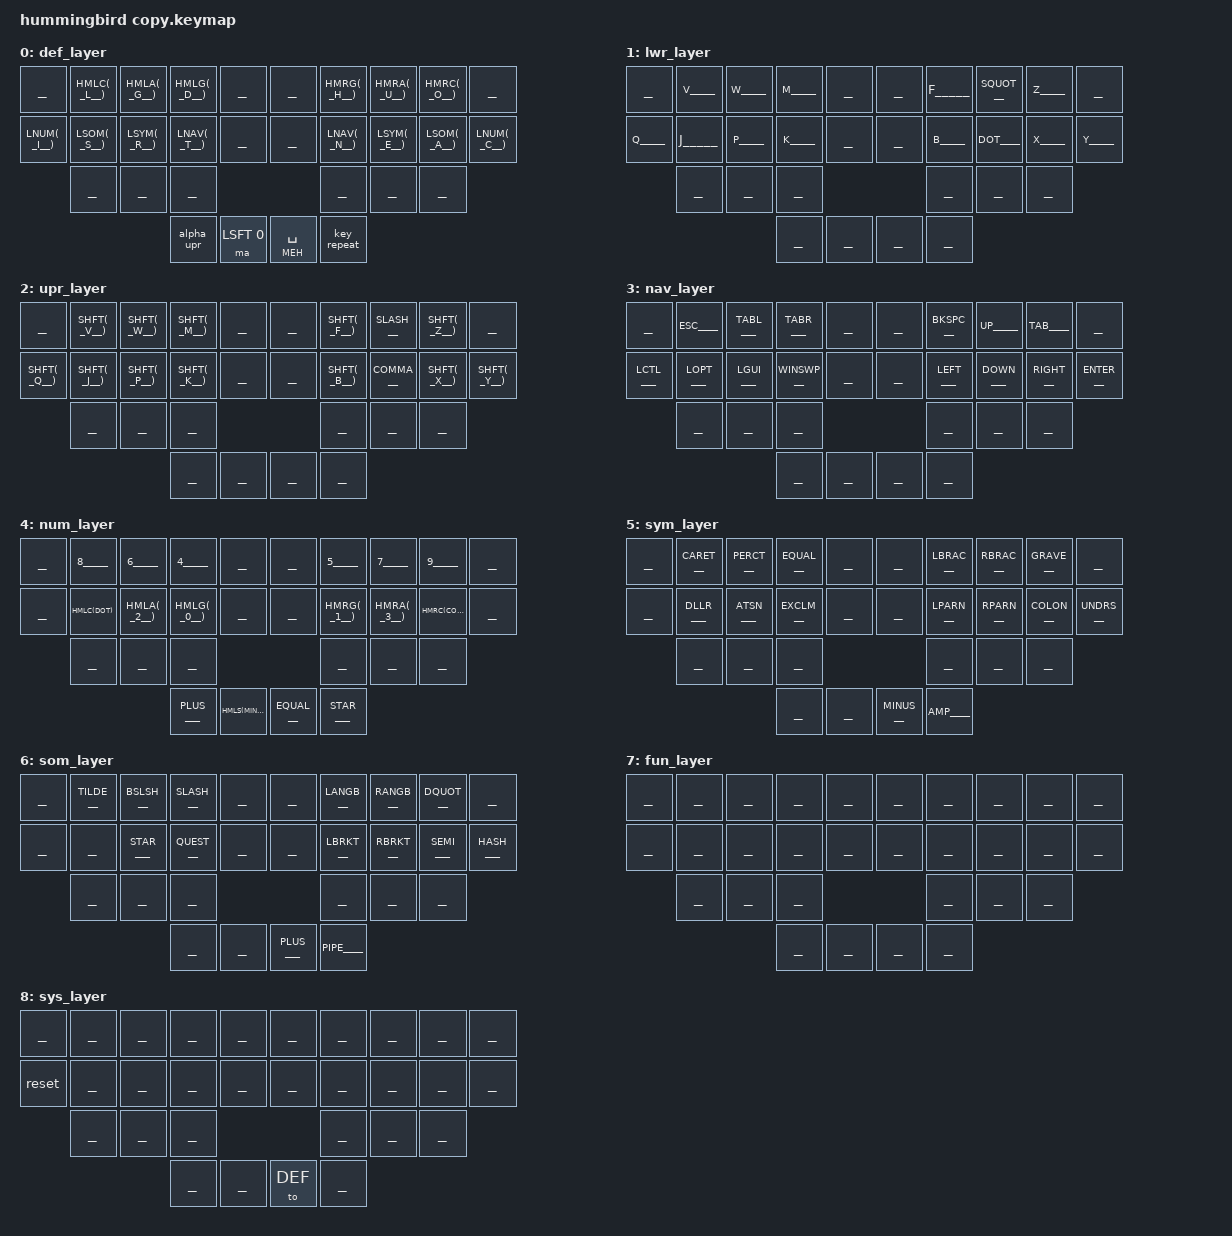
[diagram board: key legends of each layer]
#include <behaviors.dtsi>
#include <dt-bindings/zmk/keys.h>
#include <dt-bindings/zmk/bt.h>

#include "./helpers.h"
#include "./keycodes.h"

#define DEF 0
#define LWR 1
#define UPR 2
#define NAV 3
#define NUM 4
#define SYM 5
#define SOM 6
#define FUN 7
#define SYS 8

&mt {
  tapping-term-ms = <201>;
  flavor = "tap-preferred";
};

&sk {
  release-after-ms = <2000>;
  quick-release;
};

/**
 * Homerow Mod
 */
ZMK_BEHAVIOR(homerow_mod, hold_tap,
  flavor = "tap-preferred";
  tapping-term-ms = <300>;
  quick-tap-ms = <250>;
  bindings = <&kp>, <&kp>;
)

#define HM(LAYER, KEY) &homerow_mod LAYER KEY 

#define HMLG(KEY) &homerow_mod LEFT_GUI      KEY 
#define HMLA(KEY) &homerow_mod LEFT_ALT      KEY 
#define HMLC(KEY) &homerow_mod LEFT_CONTROL  KEY 
#define HMLS(KEY) &homerow_mod LEFT_SHIFT    KEY 

#define HMRG(KEY) &homerow_mod RIGHT_GUI     KEY 
#define HMRA(KEY) &homerow_mod RIGHT_ALT     KEY 
#define HMRC(KEY) &homerow_mod RIGHT_CONTROL KEY 
#define HMRS(KEY) &homerow_mod RIGHT_SHIFT   KEY 

/**
 * Homerow Layer
 */
ZMK_BEHAVIOR(homerow_layer, hold_tap,
  flavor = "tap-preferred";
  tapping-term-ms = <220>;
  quick-tap-ms = <250>;
  bindings = <&mo>, <&kp>;
)

#define HL(LAYER, KEY) &homerow_mod LAYER KEY 

#define LNAV(KEY) &homerow_layer NAV KEY 
#define LNUM(KEY) &homerow_layer NUM KEY 
#define LSYM(KEY) &homerow_layer SYM KEY 
#define LSOM(KEY) &homerow_layer SOM KEY 

/**
 * 
 */
ZMK_BEHAVIOR(alpha_lwr, macro,
  bindings = <&sl LWR>;
)

ZMK_BEHAVIOR(ma, hold_tap,
  flavor = "tap-preferred";
  tapping-term-ms = <220>;
  quick-tap-ms = <250>;
  bindings = <&sk>, <&alpha_lwr>;
)

ZMK_BEHAVIOR(alpha_upr, macro,
  bindings = <&sl UPR>;
)

#define SHFT(KEY) &kp LS(KEY)


ZMK_LAYER(def_layer,
// ╭─────────────┬─────────────┬─────────────┬─────────────┬─────────────╮   ╭─────────────┬─────────────┬─────────────┬─────────────┬─────────────╮
     ___________   HMLC(__L__)   HMLA(__G__)   HMLG(__D__)   ___________       ___________   HMRG(__H__)   HMRA(__U__)   HMRC(__O__)   ___________ 
// ├─────────────┼─────────────┼─────────────┼─────────────┼─────────────┤   ├─────────────┼─────────────┼─────────────┼─────────────┼─────────────┤
     LNUM(__I__)   LSOM(__S__)   LSYM(__R__)   LNAV(__T__)   ___________       ___________   LNAV(__N__)   LSYM(__E__)   LSOM(__A__)   LNUM(__C__) 
// ├─────────────┼─────────────┼─────────────┼─────────────┼─────────────┤   ╰─────────────┼─────────────┼─────────────┼─────────────┼─────────────╯
                   ___________   ___________   ___________                                   ___________   ___________   ___________ 
//               ╰─────────────┼─────────────┼─────────────╯                               ╰─────────────┴─────────────┴─────────────╯
                                               &alpha_upr    &ma LSFT 0        &mt MEH SPC   &key_repeat
//                                           ╰─────────────┴─────────────╯   ╰─────────────┴─────────────╯
)


ZMK_LAYER(lwr_layer,
// ╭─────────────┬─────────────┬─────────────┬─────────────┬─────────────╮   ╭─────────────┬─────────────┬─────────────┬─────────────┬─────────────╮
     ___________   _____V_____   _____W_____   _____M_____   ___________       ___________   _____F_____   ___SQUOT___   _____Z_____   ___________ 
// ├─────────────┼─────────────┼─────────────┼─────────────┼─────────────┤   ├─────────────┼─────────────┼─────────────┼─────────────┼─────────────┤
     _____Q_____   _____J_____   _____P_____   _____K_____   ___________       ___________   _____B_____   ____DOT____   _____X_____   _____Y_____ 
// ├─────────────┼─────────────┼─────────────┼─────────────┼─────────────┤   ╰─────────────┼─────────────┼─────────────┼─────────────┼─────────────╯
                   ___________   ___________   ___________                                   ___________   ___________   ___________ 
//               ╰─────────────┼─────────────┼─────────────╯                               ╰─────────────┴─────────────┴─────────────╯
                                               ___________   ___________       ___________   ___________
//                                           ╰─────────────┴─────────────╯   ╰─────────────┴─────────────╯
)

ZMK_LAYER(upr_layer,
// ╭─────────────┬─────────────┬─────────────┬─────────────┬─────────────╮   ╭─────────────┬─────────────┬─────────────┬─────────────┬─────────────╮
     ___________   SHFT(__V__)   SHFT(__W__)   SHFT(__M__)   ___________       ___________   SHFT(__F__)   ___SLASH___   SHFT(__Z__)   ___________ 
// ├─────────────┼─────────────┼─────────────┼─────────────┼─────────────┤   ├─────────────┼─────────────┼─────────────┼─────────────┼─────────────┤
     SHFT(__Q__)   SHFT(__J__)   SHFT(__P__)   SHFT(__K__)   ___________       ___________   SHFT(__B__)   ___COMMA___   SHFT(__X__)   SHFT(__Y__) 
// ├─────────────┼─────────────┼─────────────┼─────────────┼─────────────┤   ╰─────────────┼─────────────┼─────────────┼─────────────┼─────────────╯
                   ___________   ___________   ___________                                   ___________   ___________   ___________ 
//               ╰─────────────┼─────────────┼─────────────╯                               ╰─────────────┴─────────────┴─────────────╯
                                               ___________   ___________       ___________   ___________
//                                           ╰─────────────┴─────────────╯   ╰─────────────┴─────────────╯
)

ZMK_LAYER(nav_layer,
// ╭─────────────┬─────────────┬─────────────┬─────────────┬─────────────╮   ╭─────────────┬─────────────┬─────────────┬─────────────┬─────────────╮
     ___________   ____ESC____   ___TABL____   ___TABR____   ___________       ___________   ___BKSPC___   ____UP_____   ____TAB____   ___________ 
// ├─────────────┼─────────────┼─────────────┼─────────────┼─────────────┤   ├─────────────┼─────────────┼─────────────┼─────────────┼─────────────┤
     ___LCTL____   ___LOPT____   ___LGUI____   __WINSWP___  ___________       ___________   ___LEFT____   ___DOWN____   ___RIGHT___   ___ENTER___ 
// ├─────────────┼─────────────┼─────────────┼─────────────┼─────────────┤   ╰─────────────┼─────────────┼─────────────┼─────────────┼─────────────╯
                   ___________   ___________   ___________                                   ___________   ___________   ___________ 
//               ╰─────────────┼─────────────┼─────────────╯                               ╰─────────────┴─────────────┴─────────────╯
                                               ___________   ___________       ___________   ___________
//                                           ╰─────────────┴─────────────╯   ╰─────────────┴─────────────╯
)

ZMK_LAYER(num_layer,
// ╭─────────────┬─────────────┬─────────────┬─────────────┬─────────────╮   ╭─────────────┬─────────────┬─────────────┬─────────────┬─────────────╮
     ___________   _____8_____   _____6_____   _____4_____   ___________       ___________   _____5_____   _____7_____   _____9_____   ___________ 
// ├─────────────┼─────────────┼─────────────┼─────────────┼─────────────┤   ├─────────────┼─────────────┼─────────────┼─────────────┼─────────────┤
     ___________   HMLC(DOT)     HMLA(__2__)   HMLG(__0__)   ___________       ___________   HMRG(__1__)   HMRA(__3__)   HMRC(COMMA)   ___________ 
// ├─────────────┼─────────────┼─────────────┼─────────────┼─────────────┤   ╰─────────────┼─────────────┼─────────────┼─────────────┼─────────────╯
                   ___________   ___________   ___________                                   ___________   ___________   ___________ 
//               ╰─────────────┼─────────────┼─────────────╯                               ╰─────────────┴─────────────┴─────────────╯
                                               ___PLUS____   HMLS(MINUS)       ___EQUAL___   ___STAR____
//                                           ╰─────────────┴─────────────╯   ╰─────────────┴─────────────╯
)

ZMK_LAYER(sym_layer,
// ╭─────────────┬─────────────┬─────────────┬─────────────┬─────────────╮   ╭─────────────┬─────────────┬─────────────┬─────────────┬─────────────╮
     ___________   ___CARET___   ___PERCT___   ___EQUAL___   ___________       ___________   ___LBRAC___   ___RBRAC___   ___GRAVE___   ___________ 
// ├─────────────┼─────────────┼─────────────┼─────────────┼─────────────┤   ├─────────────┼─────────────┼─────────────┼─────────────┼─────────────┤
     ___________   ___DLLR____   ___ATSN____   ___EXCLM___   ___________       ___________   ___LPARN___   ___RPARN___   ___COLON___   ___UNDRS___ 
// ├─────────────┼─────────────┼─────────────┼─────────────┼─────────────┤   ╰─────────────┼─────────────┼─────────────┼─────────────┼─────────────╯
                   ___________   ___________   ___________                                   ___________   ___________   ___________ 
//               ╰─────────────┼─────────────┼─────────────╯                               ╰─────────────┴─────────────┴─────────────╯
                                               ___________   ___________       ___MINUS___   ____AMP____
//                                           ╰─────────────┴─────────────╯   ╰─────────────┴─────────────╯
)

ZMK_LAYER(som_layer,
// ╭─────────────┬─────────────┬─────────────┬─────────────┬─────────────╮   ╭─────────────┬─────────────┬─────────────┬─────────────┬─────────────╮
     ___________   ___TILDE___   ___BSLSH___   ___SLASH___   ___________       ___________   ___LANGB___   ___RANGB___   ___DQUOT___   ___________ 
// ├─────────────┼─────────────┼─────────────┼─────────────┼─────────────┤   ├─────────────┼─────────────┼─────────────┼─────────────┼─────────────┤
     ___________   ___________   ___STAR____   ___QUEST___   ___________       ___________   ___LBRKT___   ___RBRKT___   ___SEMI____   ___HASH____ 
// ├─────────────┼─────────────┼─────────────┼─────────────┼─────────────┤   ╰─────────────┼─────────────┼─────────────┼─────────────┼─────────────╯
                   ___________   ___________   ___________                                   ___________   ___________   ___________ 
//               ╰─────────────┼─────────────┼─────────────╯                               ╰─────────────┴─────────────┴─────────────╯
                                               ___________   ___________       ___PLUS____   ___PIPE____
//                                           ╰─────────────┴─────────────╯   ╰─────────────┴─────────────╯
)

ZMK_LAYER(fun_layer,
// ╭─────────────┬─────────────┬─────────────┬─────────────┬─────────────╮   ╭─────────────┬─────────────┬─────────────┬─────────────┬─────────────╮
     ___________   ___________   ___________   ___________   ___________       ___________   ___________   ___________   ___________   ___________ 
// ├─────────────┼─────────────┼─────────────┼─────────────┼─────────────┤   ├─────────────┼─────────────┼─────────────┼─────────────┼─────────────┤
     ___________   ___________   ___________   ___________   ___________       ___________   ___________   ___________   ___________   ___________ 
// ├─────────────┼─────────────┼─────────────┼─────────────┼─────────────┤   ╰─────────────┼─────────────┼─────────────┼─────────────┼─────────────╯
                   ___________   ___________   ___________                                   ___________   ___________   ___________ 
//               ╰─────────────┼─────────────┼─────────────╯                               ╰─────────────┴─────────────┴─────────────╯
                                               ___________   ___________       ___________   ___________
//                                           ╰─────────────┴─────────────╯   ╰─────────────┴─────────────╯
)

ZMK_LAYER(sys_layer,
// ╭─────────────┬─────────────┬─────────────┬─────────────┬─────────────╮   ╭─────────────┬─────────────┬─────────────┬─────────────┬─────────────╮
     ___________   ___________   ___________   ___________   ___________       ___________   ___________   ___________   ___________   ___________ 
// ├─────────────┼─────────────┼─────────────┼─────────────┼─────────────┤   ├─────────────┼─────────────┼─────────────┼─────────────┼─────────────┤
     &reset        ___________   ___________   ___________   ___________       ___________   ___________   ___________   ___________   ___________ 
// ├─────────────┼─────────────┼─────────────┼─────────────┼─────────────┤   ╰─────────────┼─────────────┼─────────────┼─────────────┼─────────────╯
                   ___________   ___________   ___________                                   ___________   ___________   ___________ 
//               ╰─────────────┼─────────────┼─────────────╯                               ╰─────────────┴─────────────┴─────────────╯
                                               ___________   ___________       &to DEF       ___________
//                                           ╰─────────────┴─────────────╯   ╰─────────────┴─────────────╯
)

/*                KEY POSITIONS

  ╭────────────────────╮ ╭────────────────────╮
  │  0   1   2   3   4 │ │  5   6   7   8   9 │
  │ 10  11  12  13  14 │ │ 15  16  17  18  19 │ 
  │     20  21  22     │ │     23  24 25      │
  ╰───────────╮ 26  27 │ │ 28  29 ╭───────────╯
              ╰────────╯ ╰────────╯
*/

ZMK_COMBO(to_sys, &to SYS, 11 12, SYM)



/**
 * TEMPLATES
 
// ╭─────────────┬─────────────┬─────────────┬─────────────┬─────────────╮   ╭─────────────┬─────────────┬─────────────┬─────────────┬─────────────╮
     ___________   ___________   ___________   ___________   ___________       ___________   ___________   ___________   ___________   ___________ 
// ├─────────────┼─────────────┼─────────────┼─────────────┼─────────────┤   ├─────────────┼─────────────┼─────────────┼─────────────┼─────────────┤
     ___________   ___________   ___________   ___________   ___________       ___________   ___________   ___________   ___________   ___________ 
// ├─────────────┼─────────────┼─────────────┼─────────────┼─────────────┤   ╰─────────────┼─────────────┼─────────────┼─────────────┼─────────────╯
                   ___________   ___________   ___________                                   ___________   ___________   ___________ 
//               ╰─────────────┼─────────────┼─────────────╯                               ╰─────────────┴─────────────┴─────────────╯
                                               ___________   ___________       ___________   ___________
//                                           ╰─────────────┴─────────────╯   ╰─────────────┴─────────────╯

// ╭─────────────┬─────────────┬─────────────┬─────────────┬─────────────╮   ╭─────────────┬─────────────┬─────────────┬─────────────┬─────────────╮
     XXXXXXXXXXX   XXXXXXXXXXX   XXXXXXXXXXX   XXXXXXXXXXX       XXXXXXXXXXX   XXXXXXXXXXX   XXXXXXXXXXX   XXXXXXXXXXX   XXXXXXXXXXX 
// ├─────────────┼─────────────┼─────────────┼─────────────┼─────────────┤   ├─────────────┼─────────────┼─────────────┼─────────────┼─────────────┤
     XXXXXXXXXXX   XXXXXXXXXXX   XXXXXXXXXXX   XXXXXXXXXXX   XXXXXXXXXXX       XXXXXXXXXXX   XXXXXXXXXXX   XXXXXXXXXXX   XXXXXXXXXXX   XXXXXXXXXXX 
// ├─────────────┼─────────────┼─────────────┼─────────────┼─────────────┤   ╰─────────────┼─────────────┼─────────────┼─────────────┼─────────────╯
                   XXXXXXXXXXX   XXXXXXXXXXX   XXXXXXXXXXX                                   XXXXXXXXXXX   XXXXXXXXXXX   XXXXXXXXXXX 
//               ╰─────────────┼─────────────┼─────────────╯                               ╰─────────────┴─────────────┴─────────────╯
                                               XXXXXXXXXXX   XXXXXXXXXXX       XXXXXXXXXXX   XXXXXXXXXXX
//                                           ╰─────────────┴─────────────╯   ╰─────────────┴─────────────╯
*/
